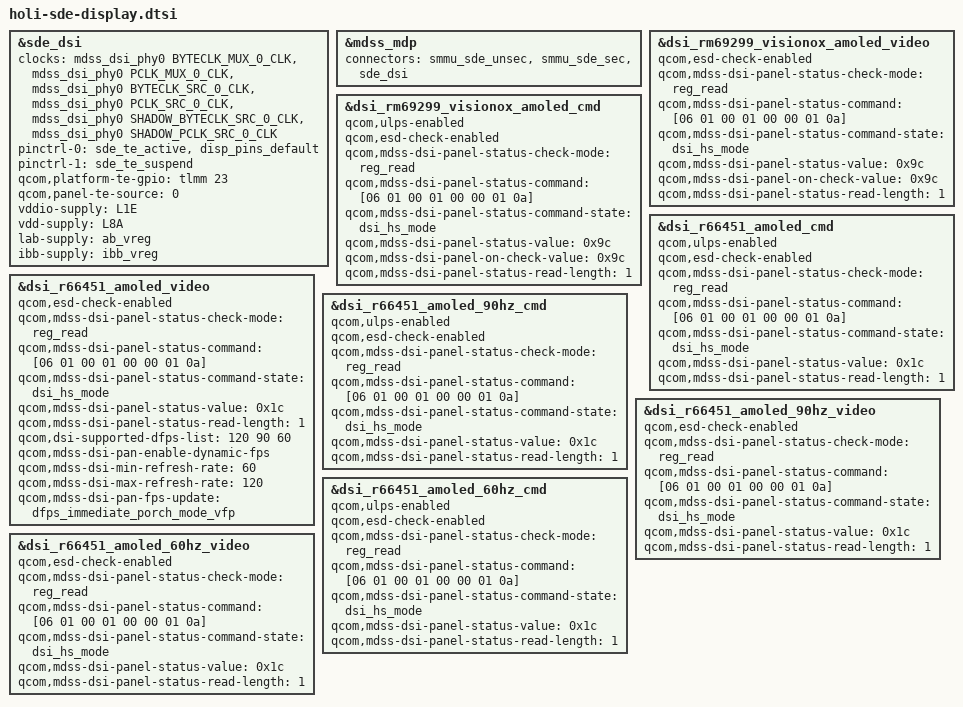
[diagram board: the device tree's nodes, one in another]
#include "holi-sde-display-common.dtsi"

&sde_dsi {
	clocks = <&mdss_dsi_phy0 BYTECLK_MUX_0_CLK>,
		 <&mdss_dsi_phy0 PCLK_MUX_0_CLK>,
		 <&mdss_dsi_phy0 BYTECLK_SRC_0_CLK>,
		 <&mdss_dsi_phy0 PCLK_SRC_0_CLK>,
		 <&mdss_dsi_phy0 SHADOW_BYTECLK_SRC_0_CLK>,
		 <&mdss_dsi_phy0 SHADOW_PCLK_SRC_0_CLK>;
	clock-names = "mux_byte_clk0", "mux_pixel_clk0",
			"src_byte_clk0", "src_pixel_clk0",
			"shadow_byte_clk0", "shadow_pixel_clk0";

	pinctrl-names = "panel_active", "panel_suspend";
	pinctrl-0 = <&sde_te_active &disp_pins_default>;
	pinctrl-1 = <&sde_te_suspend>;

	qcom,platform-te-gpio = <&tlmm 23 0>;
	qcom,panel-te-source = <0>;

	vddio-supply = <&L1E>;
	vdd-supply = <&L8A>;

	lab-supply = <&ab_vreg>;
	ibb-supply = <&ibb_vreg>;
};

&mdss_mdp {
	connectors = <&smmu_sde_unsec &smmu_sde_sec &sde_dsi>;
};

&dsi_rm69299_visionox_amoled_video {
	qcom,esd-check-enabled;
	qcom,mdss-dsi-panel-status-check-mode = "reg_read";
	qcom,mdss-dsi-panel-status-command = [06 01 00 01 00 00 01 0a];
	qcom,mdss-dsi-panel-status-command-state = "dsi_hs_mode";
	qcom,mdss-dsi-panel-status-value = <0x9c>;
	qcom,mdss-dsi-panel-on-check-value = <0x9c>;
	qcom,mdss-dsi-panel-status-read-length = <1>;
};

&dsi_rm69299_visionox_amoled_cmd {
	qcom,ulps-enabled;
	qcom,esd-check-enabled;
	qcom,mdss-dsi-panel-status-check-mode = "reg_read";
	qcom,mdss-dsi-panel-status-command = [06 01 00 01 00 00 01 0a];
	qcom,mdss-dsi-panel-status-command-state = "dsi_hs_mode";
	qcom,mdss-dsi-panel-status-value = <0x9c>;
	qcom,mdss-dsi-panel-on-check-value = <0x9c>;
	qcom,mdss-dsi-panel-status-read-length = <1>;
};

&dsi_r66451_amoled_cmd {
	qcom,ulps-enabled;
	qcom,esd-check-enabled;
	qcom,mdss-dsi-panel-status-check-mode = "reg_read";
	qcom,mdss-dsi-panel-status-command = [06 01 00 01 00 00 01 0a];
	qcom,mdss-dsi-panel-status-command-state = "dsi_hs_mode";
	qcom,mdss-dsi-panel-status-value = <0x1c>;
	qcom,mdss-dsi-panel-status-read-length = <1>;
};

&dsi_r66451_amoled_video {
	qcom,esd-check-enabled;
	qcom,mdss-dsi-panel-status-check-mode = "reg_read";
	qcom,mdss-dsi-panel-status-command = [06 01 00 01 00 00 01 0a];
	qcom,mdss-dsi-panel-status-command-state = "dsi_hs_mode";
	qcom,mdss-dsi-panel-status-value = <0x1c>;
	qcom,mdss-dsi-panel-status-read-length = <1>;
	qcom,dsi-supported-dfps-list = <120 90 60>;
	qcom,mdss-dsi-pan-enable-dynamic-fps;
	qcom,mdss-dsi-min-refresh-rate = <60>;
	qcom,mdss-dsi-max-refresh-rate = <120>;
	qcom,mdss-dsi-pan-fps-update = "dfps_immediate_porch_mode_vfp";
};

&dsi_r66451_amoled_90hz_cmd {
	qcom,ulps-enabled;
	qcom,esd-check-enabled;
	qcom,mdss-dsi-panel-status-check-mode = "reg_read";
	qcom,mdss-dsi-panel-status-command = [06 01 00 01 00 00 01 0a];
	qcom,mdss-dsi-panel-status-command-state = "dsi_hs_mode";
	qcom,mdss-dsi-panel-status-value = <0x1c>;
	qcom,mdss-dsi-panel-status-read-length = <1>;
};

&dsi_r66451_amoled_90hz_video {
	qcom,esd-check-enabled;
	qcom,mdss-dsi-panel-status-check-mode = "reg_read";
	qcom,mdss-dsi-panel-status-command = [06 01 00 01 00 00 01 0a];
	qcom,mdss-dsi-panel-status-command-state = "dsi_hs_mode";
	qcom,mdss-dsi-panel-status-value = <0x1c>;
	qcom,mdss-dsi-panel-status-read-length = <1>;
};

&dsi_r66451_amoled_60hz_cmd {
	qcom,ulps-enabled;
	qcom,esd-check-enabled;
	qcom,mdss-dsi-panel-status-check-mode = "reg_read";
	qcom,mdss-dsi-panel-status-command = [06 01 00 01 00 00 01 0a];
	qcom,mdss-dsi-panel-status-command-state = "dsi_hs_mode";
	qcom,mdss-dsi-panel-status-value = <0x1c>;
	qcom,mdss-dsi-panel-status-read-length = <1>;
};

&dsi_r66451_amoled_60hz_video {
	qcom,esd-check-enabled;
	qcom,mdss-dsi-panel-status-check-mode = "reg_read";
	qcom,mdss-dsi-panel-status-command = [06 01 00 01 00 00 01 0a];
	qcom,mdss-dsi-panel-status-command-state = "dsi_hs_mode";
	qcom,mdss-dsi-panel-status-value = <0x1c>;
	qcom,mdss-dsi-panel-status-read-length = <1>;
};

